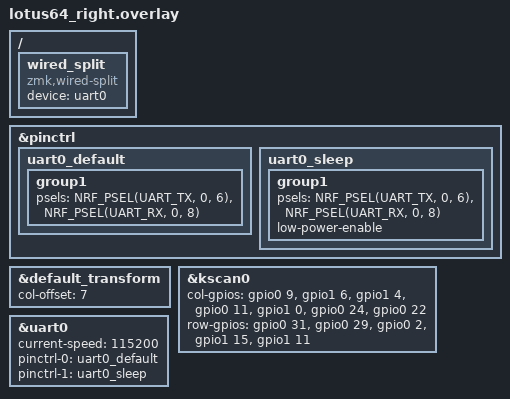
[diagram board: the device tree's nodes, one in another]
/*
 * lotus64_right.overlay - Right half specific configuration
 */

#include "lotus64.dtsi"

&pinctrl {
    uart0_default: uart0_default {
        group1 {
            psels = <NRF_PSEL(UART_TX, 0, 6)>,
                    <NRF_PSEL(UART_RX, 0, 8)>;
        };
    };

    uart0_sleep: uart0_sleep {
        group1 {
            psels = <NRF_PSEL(UART_TX, 0, 6)>,
                    <NRF_PSEL(UART_RX, 0, 8)>;
            low-power-enable;
        };
    };
};

&default_transform {
    col-offset = <7>;
};

&kscan0 {
    col-gpios
        = <&gpio0 9   GPIO_ACTIVE_HIGH>  // col 0
        , <&gpio1 6   GPIO_ACTIVE_HIGH>  // col 1
        , <&gpio1 4   GPIO_ACTIVE_HIGH>  // col 2
        , <&gpio0 11  GPIO_ACTIVE_HIGH>  // col 3
        , <&gpio1 0   GPIO_ACTIVE_HIGH>  // col 4
        , <&gpio0 24  GPIO_ACTIVE_HIGH>  // col 5
        , <&gpio0 22  GPIO_ACTIVE_HIGH>  // col 6
        ;
    row-gpios
        = <&gpio0 31 (GPIO_ACTIVE_HIGH | GPIO_PULL_DOWN)>  // row 0
        , <&gpio0 29 (GPIO_ACTIVE_HIGH | GPIO_PULL_DOWN)>  // row 1
        , <&gpio0 2  (GPIO_ACTIVE_HIGH | GPIO_PULL_DOWN)>  // row 2
        , <&gpio1 15 (GPIO_ACTIVE_HIGH | GPIO_PULL_DOWN)>  // row 3
        , <&gpio1 11 (GPIO_ACTIVE_HIGH | GPIO_PULL_DOWN)>  // row 4
        ;
};

// Add wired split UART configuration
&uart0 {
    status = "okay";
    current-speed = <115200>;
    pinctrl-0 = <&uart0_default>;
    pinctrl-1 = <&uart0_sleep>;
    pinctrl-names = "default", "sleep";
};

/ {
    wired_split {
        compatible = "zmk,wired-split";
        device = <&uart0>;
    };
};
